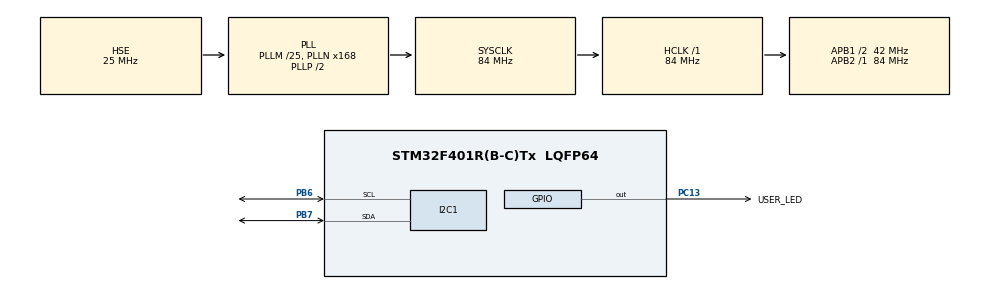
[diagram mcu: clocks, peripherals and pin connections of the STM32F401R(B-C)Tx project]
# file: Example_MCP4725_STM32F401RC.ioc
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I2C1.DutyCycle=I2C_DUTYCYCLE_2
I2C1.I2C_Mode=I2C_Fast
Mcu.Family=STM32F4
Mcu.Name=STM32F401R(B-C)Tx
Mcu.Package=LQFP64
NVIC.PriorityGroup=NVIC_PRIORITYGROUP_4
NVIC.TIM2_IRQn=true\:0\:0\:false\:false\:true\:true\:true\:true
PA13.Mode=Serial_Wire
PA13.Signal=SYS_JTMS-SWDIO
PA14.Mode=Serial_Wire
PA14.Signal=SYS_JTCK-SWCLK
PB6.Mode=I2C
PB6.Signal=I2C1_SCL
PB7.Mode=I2C
PB7.Signal=I2C1_SDA
PC13-ANTI_TAMP.GPIO_Label=USER_LED
PC13-ANTI_TAMP.GPIO_ModeDefaultOutputPP=GPIO_MODE_OUTPUT_PP
PC13-ANTI_TAMP.GPIO_PuPd=GPIO_NOPULL
PC13-ANTI_TAMP.PinState=GPIO_PIN_RESET
PC13-ANTI_TAMP.Signal=GPIO_Output
PC14-OSC32_IN.Mode=LSE-External-Oscillator
PC14-OSC32_IN.Signal=RCC_OSC32_IN
PC15-OSC32_OUT.Mode=LSE-External-Oscillator
PC15-OSC32_OUT.Signal=RCC_OSC32_OUT
PH0\ -\ OSC_IN.Mode=HSE-External-Oscillator
PH0\ -\ OSC_IN.Signal=RCC_OSC_IN
PH1\ -\ OSC_OUT.Mode=HSE-External-Oscillator
PH1\ -\ OSC_OUT.Signal=RCC_OSC_OUT
ProjectManager.HeapSize=0x200
ProjectManager.StackSize=0x400
ProjectManager.TargetToolchain=STM32CubeIDE
RCC.48MHZClocksFreq_Value=42000000
RCC.AHBFreq_Value=84000000
RCC.APB1CLKDivider=RCC_HCLK_DIV2
RCC.APB1Freq_Value=42000000
RCC.APB1TimFreq_Value=84000000
RCC.APB2Freq_Value=84000000
RCC.APB2TimFreq_Value=84000000
RCC.CortexFreq_Value=84000000
RCC.HCLKFreq_Value=84000000
RCC.HSE_VALUE=25000000
RCC.HSI_VALUE=16000000
RCC.PLLM=25
RCC.PLLN=168
RCC.PLLSourceVirtual=RCC_PLLSOURCE_HSE
RCC.SYSCLKFreq_VALUE=84000000
RCC.SYSCLKSource=RCC_SYSCLKSOURCE_PLLCLK
RCC.VCOOutputFreq_Value=168000000
TIM2.AutoReloadPreload=TIM_AUTORELOAD_PRELOAD_ENABLE
TIM2.Period=8399
TIM2.TIM_MasterOutputTrigger=TIM_TRGO_UPDATE
VP_TIM2_VS_ClockSourceINT.Mode=Internal
board=custom

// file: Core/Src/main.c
/* USER CODE BEGIN Header */
/**
  ******************************************************************************
  * @file           : main.c
  * @brief          : Main program body
  ******************************************************************************
  * @attention
  *
  * Copyright (c) 2024 STMicroelectronics.
  * All rights reserved.
  *
  * This software is licensed under terms that can be found in the LICENSE file
  * in the root directory of this software component.
  * If no LICENSE file comes with this software, it is provided AS-IS.
  *
  ******************************************************************************
  */
/* USER CODE END Header */
#include "main.h"

/* USER CODE BEGIN Includes */
#include "mcp4725.h"
/* USER CODE END Includes */

/* USER CODE BEGIN PM */
//const uint16_t signal[] = {2047,2097,2147,2198,2248,2298,2348,2398,2447,2497,2546,2595,2643,2691,2739,2786,2833,2879,2925,2970,3015,3059,3103,3145,3188,3229,3270,3310,3349,3388,3426,3462,3498,3534,3568,3601,3633,3665,3695,3725,3753,3780,3807,3832,3856,3879,3901,3922,3941,3960,3977,3993,4008,4022,4035,4046,4056,4065,4073,4079,4085,4089,4092,4093,4093,4093,4090,4087,4082,4076,4069,4061,4051,4041,4029,4015,4001,3985,3969,3951,3932,3911,3890,3868,3844,3819,3793,3767,3739,3710,3680,3649,3617,3584,3551,3516,3481,3444,3407,3369,3330,3290,3250,3209,3167,3124,3081,3037,2993,2948,2902,2856,2809,2762,2715,2667,2619,2570,2521,2472,2423,2373,2323,2273,2223,2173,2122,2072,2021,1971,1920,1870,1820,1770,1720,1670,1621,1572,1523,1474,1426,1378,1331,1284,1237,1191,1145,1100,1056,1012,969,926,884,843,803,763,724,686,649,612,577,542,509,476,444,413,383,354,326,300,274,249,225,203,182,161,142,124,108,92,78,64,52,42,32,24,17,11,6,3,0,0,0,1,4,8,14,20,28,37,47,58,71,85,100,116,133,152,171,192,214,237,261,286,313,340,368,398,428,460,492,525,559,595,631,667,705,744,783,823,864,905,948,990,1034,1078,1123,1168,1214,1260,1307,1354,1402,1450,1498,1547,1596,1646,1695,1745,1795,1845,1895,1946,1996,2046};
const uint16_t signal[] = {2046,2345,2145,1923,2199,2520,2344,2100,2350,2690,2540,2277,2499,2854,2731,2451,2643,3011,2915,2621,2781,3158,3091,2785,2911,3296,3257,2941,3034,3421,3412,3088,3146,3534,3554,3225,3247,3632,3681,3351,3337,3715,3793,3463,3413,3782,3888,3561,3476,3833,3965,3645,3525,3866,4025,3712,3559,3882,4065,3764,3578,3880,4086,3798,3582,3861,4088,3816,3570,3823,4070,3816,3544,3769,4033,3800,3502,3698,3977,3766,3446,3610,3903,3715,3375,3508,3811,3649,3292,3391,3703,3567,3196,3261,3578,3471,3089,3118,3439,3360,2971,2966,3287,3238,2844,2804,3123,3104,2709,2634,2949,2960,2567,2458,2766,2808,2420,2278,2577,2648,2269,2096,2383,2483,2115,1912,2185,2314,1961,1730,1986,2143,1808,1550,1788,1971,1657,1375,1592,1801,1509,1205,1401,1633,1367,1044,1216,1469,1232,892,1039,1312,1104,750,872,1162,986,621,716,1021,878,506,573,890,782,405,443,771,698,319,329,665,627,250,232,572,571,198,152,494,529,164,90,431,502,148,46,384,490,150,22,353,494,170,17,339,513,209,31,341,548,265,65,360,597,338,117,396,661,428,187,447,739,533,276,515,830,654,381,596,933,788,501,692,1047,934,637,801,1171,1091,786,922,1304,1257,946,1053,1445,1432,1117,1194,1592,1613,1297,1343,1743,1798,1484,1499,1898,1985,1675,1659,2054,2174,1871,1823};
const uint16_t signal_len = sizeof(signal) / sizeof(uint16_t);
#define MCP4725_ADDR	0x61
MCP4725_Handle_t mcp4725_dev = {0};
/* USER CODE END PM */

I2C_HandleTypeDef hi2c1;

TIM_HandleTypeDef htim2;

void SystemClock_Config(void);
static void MX_GPIO_Init(void);
static void MX_I2C1_Init(void);
static void MX_TIM2_Init(void);

int main(void)
{

  /* MCU Configuration--------------------------------------------------------*/

  /* Reset of all peripherals, Initializes the Flash interface and the Systick. */
  HAL_Init();

  /* Configure the system clock */
  SystemClock_Config();

  /* Initialize all configured peripherals */
  MX_GPIO_Init();
  MX_I2C1_Init();
  MX_TIM2_Init();
  /* USER CODE BEGIN 2 */
  HAL_GPIO_WritePin(USER_LED_GPIO_Port, USER_LED_Pin, GPIO_PIN_SET);
  /* USER CODE END 2 */

  /* Infinite loop */
  /* USER CODE BEGIN WHILE */

  /* Define the device address
   * According with the Datasheet; MPC4725 has the device MSB 1100 A2 A1 A0
   * Normally A2 and A1 are 0.
   * A0 use the logic level state of A0 pin.
   * */

  if( mcp4725_Init(&mcp4725_dev, &hi2c1, MCP4725_ADDR, 2047, MCP4725_NORMAL_MODE) == HAL_OK){
	  HAL_GPIO_WritePin(USER_LED_GPIO_Port, USER_LED_Pin, GPIO_PIN_RESET);
  }

  mcp4725_Write_DAC_EEPROM(&mcp4725_dev, 4048, MCP4725_NORMAL_MODE);

  HAL_TIM_Base_Start_IT(&htim2);

  while (1)
  {

	HAL_Delay(500);
	HAL_GPIO_TogglePin(USER_LED_GPIO_Port, USER_LED_Pin);

    /* USER CODE END WHILE */

  }
}

void SystemClock_Config(void)
{
  RCC_OscInitTypeDef RCC_OscInitStruct = {0};
  RCC_ClkInitTypeDef RCC_ClkInitStruct = {0};

  /** Configure the main internal regulator output voltage
  */
  __HAL_RCC_PWR_CLK_ENABLE();
  __HAL_PWR_VOLTAGESCALING_CONFIG(PWR_REGULATOR_VOLTAGE_SCALE2);

  /** Initializes the RCC Oscillators according to the specified parameters
  * in the RCC_OscInitTypeDef structure.
  */
  RCC_OscInitStruct.OscillatorType = RCC_OSCILLATORTYPE_HSE;
  RCC_OscInitStruct.HSEState = RCC_HSE_ON;
  RCC_OscInitStruct.PLL.PLLState = RCC_PLL_ON;
  RCC_OscInitStruct.PLL.PLLSource = RCC_PLLSOURCE_HSE;
  RCC_OscInitStruct.PLL.PLLM = 25;
  RCC_OscInitStruct.PLL.PLLN = 168;
  RCC_OscInitStruct.PLL.PLLP = RCC_PLLP_DIV2;
  RCC_OscInitStruct.PLL.PLLQ = 4;
  if (HAL_RCC_OscConfig(&RCC_OscInitStruct) != HAL_OK)
  {
    Error_Handler();
  }

  /** Initializes the CPU, AHB and APB buses clocks
  */
  RCC_ClkInitStruct.ClockType = RCC_CLOCKTYPE_HCLK|RCC_CLOCKTYPE_SYSCLK
                              |RCC_CLOCKTYPE_PCLK1|RCC_CLOCKTYPE_PCLK2;
  RCC_ClkInitStruct.SYSCLKSource = RCC_SYSCLKSOURCE_PLLCLK;
  RCC_ClkInitStruct.AHBCLKDivider = RCC_SYSCLK_DIV1;
  RCC_ClkInitStruct.APB1CLKDivider = RCC_HCLK_DIV2;
  RCC_ClkInitStruct.APB2CLKDivider = RCC_HCLK_DIV1;

  if (HAL_RCC_ClockConfig(&RCC_ClkInitStruct, FLASH_LATENCY_2) != HAL_OK)
  {
    Error_Handler();
  }
}

static void MX_I2C1_Init(void)
{

  hi2c1.Instance = I2C1;
  hi2c1.Init.ClockSpeed = 400000;
  hi2c1.Init.DutyCycle = I2C_DUTYCYCLE_2;
  hi2c1.Init.OwnAddress1 = 0;
  hi2c1.Init.AddressingMode = I2C_ADDRESSINGMODE_7BIT;
  hi2c1.Init.DualAddressMode = I2C_DUALADDRESS_DISABLE;
  hi2c1.Init.OwnAddress2 = 0;
  hi2c1.Init.GeneralCallMode = I2C_GENERALCALL_DISABLE;
  hi2c1.Init.NoStretchMode = I2C_NOSTRETCH_DISABLE;
  if (HAL_I2C_Init(&hi2c1) != HAL_OK)
  {
    Error_Handler();
  }

}

static void MX_TIM2_Init(void)
{

  TIM_ClockConfigTypeDef sClockSourceConfig = {0};
  TIM_MasterConfigTypeDef sMasterConfig = {0};

  htim2.Instance = TIM2;
  htim2.Init.Prescaler = 0;
  htim2.Init.CounterMode = TIM_COUNTERMODE_UP;
  htim2.Init.Period = 8399;
  htim2.Init.ClockDivision = TIM_CLOCKDIVISION_DIV1;
  htim2.Init.AutoReloadPreload = TIM_AUTORELOAD_PRELOAD_ENABLE;
  if (HAL_TIM_Base_Init(&htim2) != HAL_OK)
  {
    Error_Handler();
  }
  sClockSourceConfig.ClockSource = TIM_CLOCKSOURCE_INTERNAL;
  if (HAL_TIM_ConfigClockSource(&htim2, &sClockSourceConfig) != HAL_OK)
  {
    Error_Handler();
  }
  sMasterConfig.MasterOutputTrigger = TIM_TRGO_UPDATE;
  sMasterConfig.MasterSlaveMode = TIM_MASTERSLAVEMODE_DISABLE;
  if (HAL_TIMEx_MasterConfigSynchronization(&htim2, &sMasterConfig) != HAL_OK)
  {
    Error_Handler();
  }

}

static void MX_GPIO_Init(void)
{
  GPIO_InitTypeDef GPIO_InitStruct = {0};

  /* GPIO Ports Clock Enable */
  __HAL_RCC_GPIOC_CLK_ENABLE();
  __HAL_RCC_GPIOH_CLK_ENABLE();
  __HAL_RCC_GPIOA_CLK_ENABLE();
  __HAL_RCC_GPIOB_CLK_ENABLE();

  /*Configure GPIO pin Output Level */
  HAL_GPIO_WritePin(USER_LED_GPIO_Port, USER_LED_Pin, GPIO_PIN_RESET);

  /*Configure GPIO pin : USER_LED_Pin */
  GPIO_InitStruct.Pin = USER_LED_Pin;
  GPIO_InitStruct.Mode = GPIO_MODE_OUTPUT_PP;
  GPIO_InitStruct.Pull = GPIO_NOPULL;
  GPIO_InitStruct.Speed = GPIO_SPEED_FREQ_LOW;
  HAL_GPIO_Init(USER_LED_GPIO_Port, &GPIO_InitStruct);

}

/* USER CODE BEGIN 4 */

void HAL_TIM_PeriodElapsedCallback(TIM_HandleTypeDef *htim)
{
	static uint16_t cnt = 0;

	mcp4725_Write_DAC_Register(&mcp4725_dev, signal[cnt]);

	cnt++;
	if( cnt == signal_len)	cnt = 0;

}

/* USER CODE END 4 */

void Error_Handler(void)
{
  __disable_irq();
  while (1)
  {
  }
}
